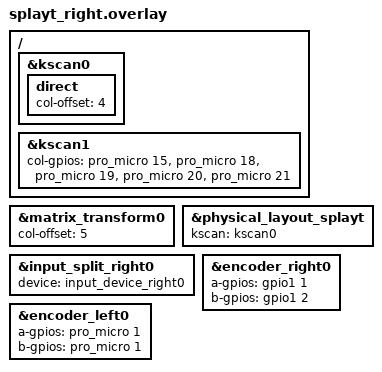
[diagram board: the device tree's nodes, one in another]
#include "splayt.dtsi"

/ {

    &kscan0 {
        direct {
            col-offset = <4>;
        };
    };

    &kscan1 {
        col-gpios
            = <&pro_micro 15 GPIO_ACTIVE_HIGH>
            , <&pro_micro 18 GPIO_ACTIVE_HIGH>
            , <&pro_micro 19 GPIO_ACTIVE_HIGH>
            , <&pro_micro 20 GPIO_ACTIVE_HIGH>
            , <&pro_micro 21 GPIO_ACTIVE_HIGH>
            ;
    };
};

&matrix_transform0 {
    col-offset = <5>;
};

&physical_layout_splayt {
    kscan = <&kscan0>;
};
// == Input devices ==
// Enabling input-split for its own input devices
// Adding input devices and assigning them to input-split
&input_split_right0 {
    status = "okay";
    device = <&input_device_right0>;
};

&encoder_right0 {
    a-gpios = <&gpio1 1 (GPIO_ACTIVE_HIGH | GPIO_PULL_UP)>;
    b-gpios = <&gpio1 2 (GPIO_ACTIVE_HIGH | GPIO_PULL_UP)>;
    status = "okay";
};

// Assigning dummy pins to other part's encoders
// just to satisfy the devicetree requirements.
// No code will be compiled for these disabled encoders.
&encoder_left0 {
    a-gpios = <&pro_micro 1 (GPIO_ACTIVE_HIGH | GPIO_PULL_UP)>;
    b-gpios = <&pro_micro 1 (GPIO_ACTIVE_HIGH | GPIO_PULL_UP)>;
};

